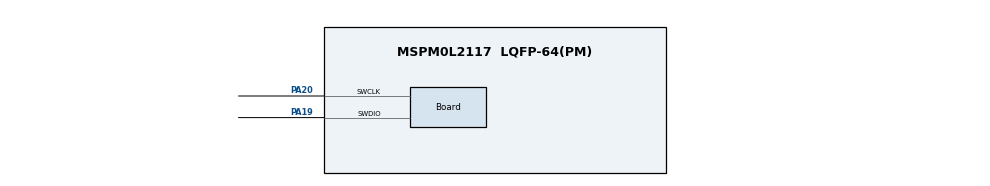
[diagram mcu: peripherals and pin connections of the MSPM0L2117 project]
/**
  */
//@cliArgs --device "MSPM0L211x" --package "LQFP-64(PM)" --part "Default"
//@v2CliArgs --device "MSPM0L2117" --package "LQFP-64(PM)"
// @cliArgs --board /ti/boards/LP_MSPM0L2117 --rtos nortos

/**
 * Import the modules used in this configuration.
 */
const SYSCTL        = scripting.addModule("/ti/driverlib/SYSCTL");
const ProjectConfig = scripting.addModule("/ti/project_config/ProjectConfig");

/**
 * Write custom configuration values to the imported modules.
 */
SYSCTL.clockTreeEn = true;

const Board                       = scripting.addModule("/ti/driverlib/Board", {}, false);
Board.peripheral.$assign          = "DEBUGSS";
Board.peripheral.swclkPin.$assign = "PA20";
Board.peripheral.swdioPin.$assign = "PA19";

ProjectConfig.genLibCMSIS        = true;
ProjectConfig.migrationCondition = true;
